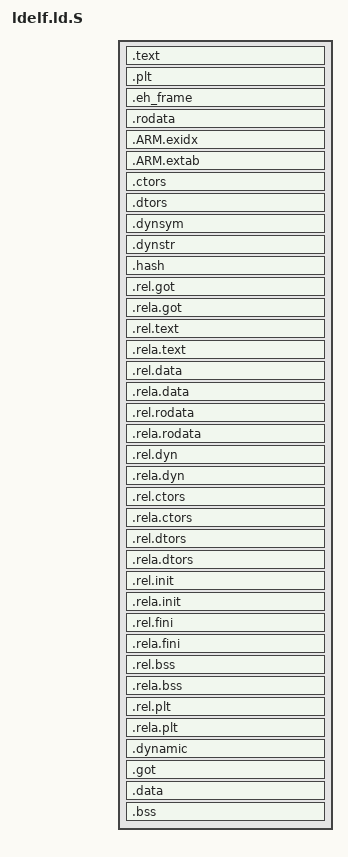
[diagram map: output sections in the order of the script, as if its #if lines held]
/* SPDX-License-Identifier: BSD-2-Clause */
/*
 * Copyright (c) 2014, STMicroelectronics International N.V.
 * Copyright (c) 2016-2019, Linaro Limited
 */

#ifdef ARM32
OUTPUT_FORMAT("elf32-littlearm")
OUTPUT_ARCH(arm)
#endif
#ifdef ARM64
OUTPUT_FORMAT("elf64-littleaarch64")
OUTPUT_ARCH(aarch64)
#endif

ENTRY(_ldelf_start)
SECTIONS {
	.text : {
		__text_start = .;
		*(.text._ldelf_start)
		*(.text .text.*)
		*(.stub)
		*(.glue_7)
		*(.glue_7t)
		*(.gnu.linkonce.t.*)
		/* Workaround for an erratum in ARM's VFP11 coprocessor */
		*(.vfp11_veneer)
		__text_end = .;
	}
        .plt : { *(.plt) }

	.eh_frame : { *(.eh_frame) }
	.rodata : {
		*(.gnu.linkonce.r.*)
		*(.rodata .rodata.*)
	}
	/* .ARM.exidx is sorted, so has to go in its own output section.  */
	.ARM.exidx : { *(.ARM.exidx* .gnu.linkonce.armexidx.*) }
	.ARM.extab : { *(.ARM.extab*) }
        .ctors : { *(.ctors) }
        .dtors : { *(.dtors) }
	.dynsym : { *(.dynsym) }
	.dynstr : { *(.dynstr) }
	.hash : { *(.hash) }

	/*
	 * Relocation sections may be aligned on 4 or 8 bytes. With ALIGN(8)
	 * we avoid any padding between __reloc_begin and the first relocation.
	 */
	. = ALIGN(8);
	__reloc_begin = .;
	.rel.got : { *(.rel.got) }
	.rela.got : { *(.rela.got) }
	.rel.text : { *(.rel.text) *(.rel.gnu.linkonce.t*) }
	.rela.text : { *(.rela.text) *(.rela.gnu.linkonce.t*) }
	.rel.data : { *(.rel.data) *(.rel.gnu.linkonce.d*) }
	.rela.data : { *(.rela.data) *(.rela.gnu.linkonce.d*) }
	.rel.rodata : { *(.rel.rodata) *(.rel.gnu.linkonce.r*) }
	.rela.rodata : { *(.rela.rodata) *(.rela.gnu.linkonce.r*) }
	.rel.dyn : { *(.rel.dyn) }
	.rela.dyn : { *(.rela.dyn) }
	.rel.ctors : { *(.rel.ctors) }
	.rela.ctors : { *(.rela.ctors) }
	.rel.dtors : { *(.rel.dtors) }
	.rela.dtors : { *(.rela.dtors) }
	.rel.init : { *(.rel.init) }
	.rela.init : { *(.rela.init) }
	.rel.fini : { *(.rel.fini) }
	.rela.fini : { *(.rela.fini) }
	.rel.bss : { *(.rel.bss) }
	.rela.bss : { *(.rela.bss) }
	.rel.plt : { *(.rel.plt) }
	.rela.plt : { *(.rela.plt) }
	__reloc_end = .;

	/* Page align to allow dropping execute bit for RW data */
	. = ALIGN(4096);

	.dynamic : { *(.dynamic) }
	.got : { *(.got.plt) *(.got) }

	.data : { *(.data .data.* .gnu.linkonce.d.*) }
	.bss : { *(.bss .bss.* .gnu.linkonce.b.* COMMON) }

	/DISCARD/ : { *(.interp) }
}
